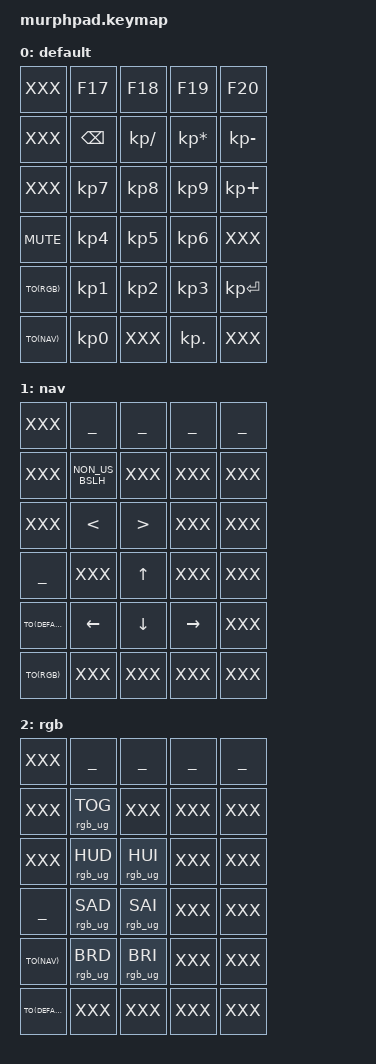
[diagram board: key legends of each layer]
/*
 * Copyright (c) 2021 The ZMK Contributors
 *
 * SPDX-License-Identifier: MIT
 */

#include <behaviors.dtsi>
#include <dt-bindings/zmk/keys.h>
#include <dt-bindings/zmk/rgb.h>
#include "murphpad.h"
#include "rgb.keymap"

#define TIMEOUT 300

&encoder_1 {
    status = "okay";
};

&spi1 {
	compatible = "nordic,nrf-spim";
	status = "okay";
	mosi-pin = <31>;
	// Unused pins, needed for SPI definition, but not used by the ws2812 driver itself.
	sck-pin = <5>;
	miso-pin = <7>;

	led_strip: ws2812@0 {
		compatible = "worldsemi,ws2812-spi";
		label = "WS2812";

		/* SPI */
		reg = <0>; /* ignored, but necessary for SPI bindings */
		spi-max-frequency = <4000000>;

		/* WS2812 */
		chain-length = <8>; /* number of LEDs */
		spi-one-frame = <0x70>;
		spi-zero-frame = <0x40>;
	};
};

/ {
	chosen {
		zmk,underglow = &led_strip;
	};
};

/ {
    
    sensors {
        compatible = "zmk,keymap-sensors";
        sensors = <&encoder_1>;
    };

    keymap0: keymap {
        compatible = "zmk,keymap";

        default_layer {
            label = "default";
            bindings = <
            // ╭─────────────────┬─────────────────┬─────────────────┬─────────────────┬─────────────────╮
                 XXX               &kp F17           &kp F18           &kp F19           &kp F20
            // ┼─────────────────┼─────────────────┼─────────────────┼─────────────────┼─────────────────┼
                 XXX               &kp BSPC          &kp KP_DIVIDE     &kp KP_MULTIPLY   &kp KP_MINUS
            // ┼─────────────────┼─────────────────┼─────────────────┼─────────────────┼─────────────────┼
                 XXX               &kp KP_N7         &kp KP_N8         &kp KP_N9         &kp KP_PLUS
            // ┼─────────────────┼─────────────────┼─────────────────┼─────────────────┼─────────────────┼
                 &kp C_MUTE        &kp KP_N4         &kp KP_N5         &kp KP_N6         XXX
            // ┼─────────────────┼─────────────────┼─────────────────┼─────────────────┼─────────────────┼
                 &TO(RGB)          &kp KP_N1         &kp KP_N2         &kp KP_N3         &kp KP_ENTER
            // ┼─────────────────┼─────────────────┼─────────────────┼─────────────────┼─────────────────┼
                 &TO(NAV)          &kp KP_N0         XXX               &kp KP_DOT        XXX
            // ╰─────────────────┼─────────────────┼─────────────────┼─────────────────┼─────────────────╯
            >;
            sensor-bindings = <&inc_dec_kp C_VOL_UP C_VOL_DN>;

        };
        
        nav_layer {
            label = "nav";
            bindings = <
            // ╭─────────────────┬─────────────────┬─────────────────┬─────────────────┬─────────────────╮
                 XXX               ___               ___               ___               ___
            // ┼─────────────────┼─────────────────┼─────────────────┼─────────────────┼─────────────────┼
                 XXX               &kp NON_US_BSLH   XXX               XXX               XXX
            // ┼─────────────────┼─────────────────┼─────────────────┼─────────────────┼─────────────────┼
                 XXX               &kp LESS_THAN     &kp GREATER_THAN  XXX               XXX
            // ┼─────────────────┼─────────────────┼─────────────────┼─────────────────┼─────────────────┼
                 ___               XXX               &kp UP            XXX               XXX
            // ┼─────────────────┼─────────────────┼─────────────────┼─────────────────┼─────────────────┼
                 &TO(DEFAULT)      &kp LEFT          &kp DOWN          &kp RIGHT         XXX
            // ┼─────────────────┼─────────────────┼─────────────────┼─────────────────┼─────────────────┼
                 &TO(RGB)          XXX               XXX               XXX               XXX
            // ╰─────────────────┼─────────────────┼─────────────────┼─────────────────┼─────────────────╯
            >;  
            sensor-bindings = <&inc_dec_kp C_VOL_UP C_VOL_DN>;
                
        };

        rgb_layer {
            label = "rgb";
            bindings = <
            // ╭─────────────────┬─────────────────┬─────────────────┬─────────────────┬─────────────────╮
                 XXX               ___               ___               ___               ___
            // ┼─────────────────┼─────────────────┼─────────────────┼─────────────────┼─────────────────┼
                 XXX               &rgb_ug RGB_TOG   XXX               XXX               XXX
            // ┼─────────────────┼─────────────────┼─────────────────┼─────────────────┼─────────────────┼
                 XXX               &rgb_ug RGB_HUD   &rgb_ug RGB_HUI   XXX               XXX
            // ┼─────────────────┼─────────────────┼─────────────────┼─────────────────┼─────────────────┼
                 ___               &rgb_ug RGB_SAD   &rgb_ug RGB_SAI   XXX               XXX
            // ┼─────────────────┼─────────────────┼─────────────────┼─────────────────┼─────────────────┼
                 &TO(NAV)          &rgb_ug RGB_BRD   &rgb_ug RGB_BRI   XXX               XXX
            // ┼─────────────────┼─────────────────┼─────────────────┼─────────────────┼─────────────────┼
                 &TO(DEFAULT)      XXX               XXX               XXX               XXX
            // ╰─────────────────┼─────────────────┼─────────────────┼─────────────────┼─────────────────╯
            >;
            sensor-bindings = <&inc_dec_kp C_VOL_UP C_VOL_DN>;
                
        };
        
    };
};
